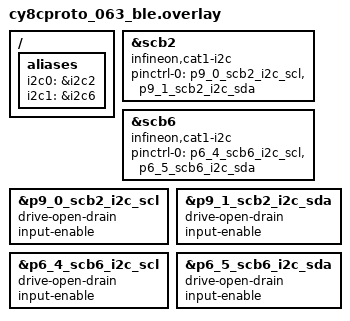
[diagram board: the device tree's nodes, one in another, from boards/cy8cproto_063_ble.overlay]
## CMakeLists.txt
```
# SPDX-License-Identifier: Apache-2.0

cmake_minimum_required(VERSION 3.20.0)
find_package(Zephyr REQUIRED HINTS $ENV{ZEPHYR_BASE})
project(i2c_slave_master)

FILE(GLOB app_sources src/*.c)
target_sources(app PRIVATE ${app_sources})
```

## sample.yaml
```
sample:
  name: I2C sample
tests:
  sample.drivers.i2c:
    tags: drivers i2c
    depends_on: i2c
    filter: dt_enabled_alias_with_parent_compat("i2c0", "i2c1")
    harness: console
    harness_config:
      type: multi_line
      ordered: true
      regex:
        - "MSR RX: 01: 0x0B"
        - "MSR RX: 02: 0x0C"
        - "MSR RX: 03: 0x0D"
        - "MSR RX: 04: 0x0E"
        - "MSR RX: 05: 0x0F"
        - "MSR RX: 06: 0x10"
        - "MSR RX: 07: 0x11"
        - "MSR RX: 08: 0x12"
        - "MSR RX: 09: 0x13"
        - "MSR RX: 10: 0x14"
```

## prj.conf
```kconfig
CONFIG_STDOUT_CONSOLE=y
CONFIG_PRINTK=y

CONFIG_I2C=y
CONFIG_LOG=y
CONFIG_HEAP_MEM_POOL_SIZE=4096
CONFIG_LOG_MODE_IMMEDIATE=y
```

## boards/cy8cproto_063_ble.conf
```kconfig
CONFIG_I2C_INFINEON_CAT1_TARGET_BUF=128
```

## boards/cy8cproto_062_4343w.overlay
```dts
/*
 * Copyright (c) 2023 Cypress Semiconductor Corporation (an Infineon company) or
 * an affiliate of Cypress Semiconductor Corporation
 *
 * SPDX-License-Identifier: Apache-2.0
 */

/{
	aliases {
		i2c0  = &i2c3;
		i2c1  = &i2c6;
	};
};

i2c6: &scb6 {
	compatible = "infineon,cat1-i2c";

	status = "okay";
	pinctrl-0 = <&p6_4_scb6_i2c_scl &p6_5_scb6_i2c_sda>;
	pinctrl-names = "default";
};

/* Configure pin control bias mode for i2c pins */
&p6_4_scb6_i2c_scl {
	drive-open-drain;
	input-enable;
};

&p6_5_scb6_i2c_sda {
	drive-open-drain;
	input-enable;
};
```

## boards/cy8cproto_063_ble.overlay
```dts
/*
 * Copyright (c) 2023 Cypress Semiconductor Corporation (an Infineon company) or
 * an affiliate of Cypress Semiconductor Corporation
 *
 * SPDX-License-Identifier: Apache-2.0
 */

 /{
	aliases {
		i2c0  = &i2c2;
		i2c1  = &i2c6;
	};
};

i2c2: &scb2 {
	compatible = "infineon,cat1-i2c";

	status = "okay";
	pinctrl-0 = <&p9_0_scb2_i2c_scl &p9_1_scb2_i2c_sda>;
	pinctrl-names = "default";
};

i2c6: &scb6 {
	compatible = "infineon,cat1-i2c";

	status = "okay";
	pinctrl-0 = <&p6_4_scb6_i2c_scl &p6_5_scb6_i2c_sda>;
	pinctrl-names = "default";
};

/* Configure pin control bias mode for i2c pins */
&p9_0_scb2_i2c_scl {
	drive-open-drain;
	input-enable;
};

&p9_1_scb2_i2c_sda {
	drive-open-drain;
	input-enable;
};

&p6_4_scb6_i2c_scl {
	drive-open-drain;
	input-enable;
};

&p6_5_scb6_i2c_sda {
	drive-open-drain;
	input-enable;
};
```

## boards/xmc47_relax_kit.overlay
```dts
/*
 * Copyright (c) 2023 Cypress Semiconductor Corporation (an Infineon company) or
 * an affiliate of Cypress Semiconductor Corporation
 *
 * SPDX-License-Identifier: Apache-2.0
 */

/ {
	aliases {
		i2c0  = &usic0ch1;
		i2c1  = &usic2ch0;
	};
};

&i2c_controller_scl_p6_2_u0c1 {
	drive-strength = "strong-sharp-edge";
	hwctrl = "disabled";
};

&i2c_controller_sda_p3_13_u0c1 {
	drive-strength = "strong-soft-edge";
	hwctrl = "disabled";
};

&usic0ch1 {
	compatible = "infineon,xmc4-i2c";
	pinctrl-0 = <&i2c_controller_scl_p6_2_u0c1 &i2c_controller_sda_p3_13_u0c1>;
	pinctrl-names = "default";
	scl-src = "DX0C";
	sda-src = "DX0D";
	interrupts = <86 1>;

	#address-cells = <1>;
	#size-cells = <0>;
	status = "okay";
};

&i2c_target_scl_p5_2_u2c0 {
	drive-strength = "strong-sharp-edge";
	hwctrl = "disabled";
};

&i2c_target_sda_p5_0_u2c0 {
	drive-strength = "strong-sharp-edge";
	hwctrl = "disabled";
};

&usic2ch0 {
	compatible = "infineon,xmc4-i2c";
	pinctrl-0 = <&i2c_target_scl_p5_2_u2c0 &i2c_target_sda_p5_0_u2c0>;
	pinctrl-names = "default";
	scl-src = "DX0A";
	sda-src = "DX0B";
	interrupts = <96 1>;

	#address-cells = <1>;
	#size-cells = <0>;
	status = "okay";
};
```

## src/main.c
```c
/*
 * Copyright (c) 2023 Cypress Semiconductor Corporation (an Infineon company) or
 * an affiliate of Cypress Semiconductor Corporation
 *
 * SPDX-License-Identifier: Apache-2.0
 */

#include <errno.h>

#include <zephyr/sys/printk.h>
#include <zephyr/device.h>
#include <zephyr/drivers/i2c.h>

#define I2C_SLAVE_ADDR 0x1EUL

int i2c_slave_write_requested_cb(struct i2c_target_config *config);
int i2c_slave_read_requested_cb(struct i2c_target_config *config, uint8_t *val);
int i2c_slave_write_received_cb(struct i2c_target_config *config, uint8_t val);
int i2c_slave_read_processed_cb(struct i2c_target_config *config, uint8_t *val);
int i2c_slave_stop_cb(struct i2c_target_config *config);
struct i2c_target_config i2c_data_cfg;
struct i2c_target_callbacks i2c_slave_cbs;

static int read_byte_from_slave(const struct device *i2c_dev, uint8_t *byte);
static int write_bytes_to_slave(const struct device *i2c_dev, uint8_t *p_to_slave_tx, uint16_t len);
static int read_bytes_from_slave(const struct device *i2c_dev, uint8_t *p_data);

uint8_t data_from_slave[16];
uint8_t test_data = 10;
uint8_t increment;

void main(void)
{
	int ret;
	uint8_t data_for_slave[3] = {0, 1, 2};
	uint8_t read_byte;

	i2c_slave_cbs.write_requested = i2c_slave_write_requested_cb;
	i2c_slave_cbs.read_requested = i2c_slave_read_requested_cb;
	i2c_slave_cbs.write_received = i2c_slave_write_received_cb;
	i2c_slave_cbs.read_processed = i2c_slave_read_processed_cb;
	i2c_slave_cbs.stop = i2c_slave_stop_cb;

	i2c_data_cfg.address = I2C_SLAVE_ADDR;
	i2c_data_cfg.callbacks = &i2c_slave_cbs;

	const struct device *dev_i2c_master = DEVICE_DT_GET(DT_ALIAS(i2c0));
	const struct device *dev_i2c_slave = DEVICE_DT_GET(DT_ALIAS(i2c1));

	printk("I2C Slave test\n");

	if (!device_is_ready(dev_i2c_master)) {
		printk("I2C Master Device is not ready.\n");
		return;
	}
	printk("I2C Master Device is ready\n");

	i2c_configure(dev_i2c_master, I2C_SPEED_SET(I2C_SPEED_FAST) | I2C_MODE_CONTROLLER);

	if (!device_is_ready(dev_i2c_slave)) {
		printk("I2C Slave Device is not ready.\n");
		return;
	}
	printk("I2C Slave Device is ready\n");

	ret = i2c_target_register(dev_i2c_slave, &i2c_data_cfg);
	if (ret) {
		printk("I2C Slave Error in configuring slave [ret %d]\n", ret);
		return;
	}


	while (1) {
		printk("=== READ BYTE ===\n");
		ret = read_byte_from_slave(dev_i2c_master, &read_byte);
		if (ret != 0) {
			printk("--> MSR: Error in reading byte: %d\n", ret);
		} else {
			printk("MSR RX: 0x%02X\n", read_byte);
		}

		printk("=== WRITE ===\n");
		for (int i = 0; i < sizeof(data_for_slave); i++) {
			data_for_slave[i] = data_for_slave[i] + 1;
		}
		ret = write_bytes_to_slave(dev_i2c_master, data_for_slave, sizeof(data_for_slave));
		if (ret != 0) {
			printk("--> MSR: Error in writing data: %d\n", ret);
		}

		printk("=== READ ===\n");
		if (read_bytes_from_slave(dev_i2c_master, data_from_slave) == 0) {
			for (uint8_t i = 0; i < 10; i++) {
				printk("MSR RX %d: 0x%02X\n", i, data_from_slave[i]);
			}
		} else {
			printk("--> MSR: Error in reading data\n");
		}

		k_msleep(10 * 1000);
	}
}

static int read_byte_from_slave(const struct device *i2c_dev, uint8_t *byte)
{
	struct i2c_msg msg;

	msg.buf = byte;
	msg.len = 1;
	msg.flags = I2C_MSG_READ | I2C_MSG_STOP;

	return i2c_transfer(i2c_dev, &msg, 1, I2C_SLAVE_ADDR);
}

static int write_bytes_to_slave(const struct device *i2c_dev, uint8_t *p_to_slave_tx, uint16_t len)
{
	struct i2c_msg msg;

	msg.buf = p_to_slave_tx;
	msg.len = len;
	msg.flags = I2C_MSG_WRITE | I2C_MSG_STOP;

	return i2c_transfer(i2c_dev, &msg, 1, I2C_SLAVE_ADDR);
}

static int read_bytes_from_slave(const struct device *i2c_dev, uint8_t *p_data)
{
	uint8_t wr_addr = 0x0C;
	struct i2c_msg msgs[2];

	msgs[0].buf = &wr_addr;
	msgs[0].len = 1U;
	msgs[0].flags = I2C_MSG_WRITE;

	msgs[1].buf = p_data;
	msgs[1].len = 10;
	msgs[1].flags = I2C_MSG_RESTART | I2C_MSG_READ | I2C_MSG_STOP;

	return i2c_transfer(i2c_dev, msgs, 2, I2C_SLAVE_ADDR);
}

int i2c_slave_write_requested_cb(struct i2c_target_config *config)
{
	printk("SLV: Wr Reg\n");
	return 0;
}

int i2c_slave_write_received_cb(struct i2c_target_config *config, uint8_t val)
{
	printk("SLV RX: 0x%02X\n", val);
	return 0;
}

int i2c_slave_read_requested_cb(struct i2c_target_config *config, uint8_t *val)
{
	*val = test_data++;
	increment = 0;
	printk("SLV TX %d: 0x%02X\n", increment, *val);
	return 0;
}

int i2c_slave_read_processed_cb(struct i2c_target_config *config, uint8_t *val)
{
	*val = test_data + increment;
	increment++;
	printk("SLV TX %d: 0x%02X\n", increment, *val);
	return 0;
}

int i2c_slave_stop_cb(struct i2c_target_config *config)
{
	printk("SLV: Stop\n");
	return 0;
}
```
